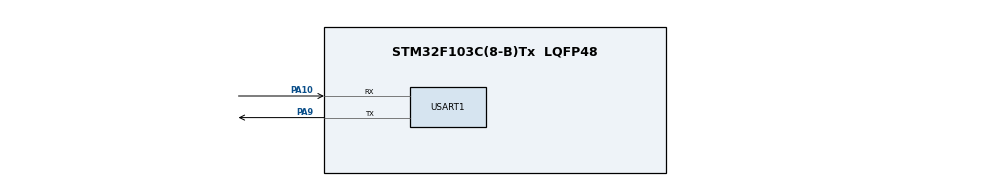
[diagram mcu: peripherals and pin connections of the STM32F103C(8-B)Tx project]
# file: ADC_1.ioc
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ADC1.Channel-1\#ChannelRegularConversion=ADC_CHANNEL_TEMPSENSOR
ADC1.NbrOfConversion=1
ADC1.NbrOfConversionFlag=1
ADC1.Rank-1\#ChannelRegularConversion=1
ADC1.SamplingTime-1\#ChannelRegularConversion=ADC_SAMPLETIME_1CYCLE_5
ADC1.master=1
Mcu.Family=STM32F1
Mcu.Name=STM32F103C(8-B)Tx
Mcu.Package=LQFP48
NVIC.PriorityGroup=NVIC_PRIORITYGROUP_4
PA10.Mode=Asynchronous
PA10.Signal=USART1_RX
PA13.Mode=JTAG_5_pins
PA13.Signal=SYS_JTMS-SWDIO
PA14.Mode=JTAG_5_pins
PA14.Signal=SYS_JTCK-SWCLK
PA15.Mode=JTAG_5_pins
PA15.Signal=SYS_JTDI
PA9.Mode=Asynchronous
PA9.Signal=USART1_TX
PB3.Mode=JTAG_5_pins
PB3.Signal=SYS_JTDO-TRACESWO
PB4.Mode=JTAG_5_pins
PB4.Signal=SYS_NJTRST
ProjectManager.HeapSize=0x200
ProjectManager.StackSize=0x400
ProjectManager.TargetToolchain=MDK-ARM V5.32
RCC.APB1Freq_Value=8000000
RCC.APB2Freq_Value=8000000
USART1.VirtualMode=VM_ASYNC
VP_ADC1_TempSens_Input.Mode=IN-TempSens
board=custom

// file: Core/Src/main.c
/* USER CODE BEGIN Header */
/**
  ******************************************************************************
  * @file           : main.c
  * @brief          : Main program body
  ******************************************************************************
  * @attention
  *
  * Copyright (c) 2023 STMicroelectronics.
  * All rights reserved.
  *
  * This software is licensed under terms that can be found in the LICENSE file
  * in the root directory of this software component.
  * If no LICENSE file comes with this software, it is provided AS-IS.
  *
  ******************************************************************************
  */
/* USER CODE END Header */
#include "main.h"
#include "adc.h"
#include "usart.h"
#include "gpio.h"

/* USER CODE BEGIN Includes */
#include <stdio.h>
/* USER CODE END Includes */

/* USER CODE BEGIN PV */
uint16_t AD_Value = 0;
double Vsense = 0;
double Temperature= 0;
/* USER CODE END PV */

void SystemClock_Config(void);

int main(void)
{

  /* MCU Configuration--------------------------------------------------------*/

  /* Reset of all peripherals, Initializes the Flash interface and the Systick. */
  HAL_Init();

  /* Configure the system clock */
  SystemClock_Config();

  /* Initialize all configured peripherals */
  MX_GPIO_Init();
  MX_ADC1_Init();
  MX_USART1_UART_Init();

  /* Infinite loop */
  while (1)
  {

    /* USER CODE BEGIN 3 */
    HAL_ADC_Start(&hadc1);
    HAL_ADC_PollForConversion(&hadc1, 50);
    if(HAL_IS_BIT_SET(HAL_ADC_GetState(&hadc1), HAL_ADC_STATE_REG_EOC))
    {
      AD_Value = HAL_ADC_GetValue(&hadc1);
    }
    Vsense = AD_Value*3300.0/4096;
    printf("V=%.1fmv\r\n", Vsense);
    Temperature = (1430 - Vsense)/4.3 + 25;
    printf("T=%.1foC\r\n", Temperature);
  }
  /* USER CODE END 3 */
}

void SystemClock_Config(void)
{
  RCC_OscInitTypeDef RCC_OscInitStruct = {0};
  RCC_ClkInitTypeDef RCC_ClkInitStruct = {0};
  RCC_PeriphCLKInitTypeDef PeriphClkInit = {0};

  /** Initializes the RCC Oscillators according to the specified parameters
  * in the RCC_OscInitTypeDef structure.
  */
  RCC_OscInitStruct.OscillatorType = RCC_OSCILLATORTYPE_HSI;
  RCC_OscInitStruct.HSIState = RCC_HSI_ON;
  RCC_OscInitStruct.HSICalibrationValue = RCC_HSICALIBRATION_DEFAULT;
  RCC_OscInitStruct.PLL.PLLState = RCC_PLL_NONE;
  if (HAL_RCC_OscConfig(&RCC_OscInitStruct) != HAL_OK)
  {
    Error_Handler();
  }

  /** Initializes the CPU, AHB and APB buses clocks
  */
  RCC_ClkInitStruct.ClockType = RCC_CLOCKTYPE_HCLK|RCC_CLOCKTYPE_SYSCLK
                              |RCC_CLOCKTYPE_PCLK1|RCC_CLOCKTYPE_PCLK2;
  RCC_ClkInitStruct.SYSCLKSource = RCC_SYSCLKSOURCE_HSI;
  RCC_ClkInitStruct.AHBCLKDivider = RCC_SYSCLK_DIV1;
  RCC_ClkInitStruct.APB1CLKDivider = RCC_HCLK_DIV1;
  RCC_ClkInitStruct.APB2CLKDivider = RCC_HCLK_DIV1;

  if (HAL_RCC_ClockConfig(&RCC_ClkInitStruct, FLASH_LATENCY_0) != HAL_OK)
  {
    Error_Handler();
  }
  PeriphClkInit.PeriphClockSelection = RCC_PERIPHCLK_ADC;
  PeriphClkInit.AdcClockSelection = RCC_ADCPCLK2_DIV2;
  if (HAL_RCCEx_PeriphCLKConfig(&PeriphClkInit) != HAL_OK)
  {
    Error_Handler();
  }
}

/* USER CODE BEGIN 4 */
int fputc (int ch, FILE *f)
{
    HAL_UART_Transmit(&huart1, (uint8_t *)&ch, 1, HAL_MAX_DELAY);
    return ch;
}

int fgetc(FILE *f)
{
    uint8_t ch = 0;
    HAL_UART_Receive(&huart1, (uint8_t *)&ch, 1, HAL_MAX_DELAY);
    return ch;
}
/* USER CODE END 4 */

void Error_Handler(void)
{
  __disable_irq();
  while (1)
  {
  }
}
